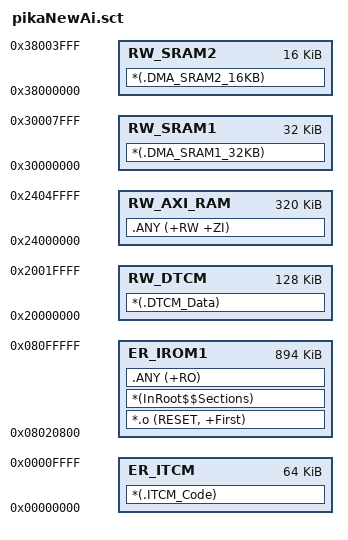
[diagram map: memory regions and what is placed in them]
LR_IROM1 0x08020800 0x000DF800 {   ; Flash区域
  ER_IROM1 0x08020800 0x000DF800 { ; 代码在Flash中执行
   *.o (RESET, +First)
   *(InRoot$$Sections)
   .ANY (+RO)
  }
  
  ; 1. 最高优先级：特定用途的紧耦合内存 (必须放在此处的变量)
  ER_ITCM 0x00000000 0x00010000 {  ; ITCM, 64KB
    *(.ITCM_Code)                  ; 仅放置显式标记的代码
  }
  
  RW_DTCM 0x20000000 0x00020000 {  ; DTCM, 128KB
    *(.DTCM_Data)                  ; 仅放置显式标记的数据
  }
  
  ; 2. 中等优先级：特定用途的DMA内存
  RW_SRAM1 0x30000000 0x00008000 { ; SRAM1, 32KB
    *(.DMA_SRAM1_32KB)             ; 仅放置显式标记的DMA1数据
  }
  
  RW_SRAM2 0x38000000 0x00004000 { ; SRAM2, 16KB
    *(.DMA_SRAM2_16KB)             ; 仅放置显式标记的DMA2数据
  }
  
  ; 3. 最低优先级（默认池）：AXI RAM - 所有“普通”变量将落在这里
  RW_AXI_RAM 0x24000000 0x00050000 { ; AXI RAM, 假设512KB (请核对手册!)
    .ANY (+RW +ZI)                 ; 捕获所有未被上述规则分配的变量
  }
}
